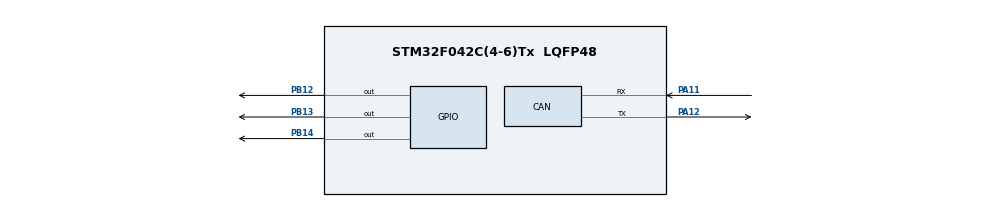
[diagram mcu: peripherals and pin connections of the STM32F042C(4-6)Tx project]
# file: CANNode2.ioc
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CAN.CalculateTimeQuantum=2000.0
Mcu.Family=STM32F0
Mcu.Name=STM32F042C(4-6)Tx
Mcu.Package=LQFP48
PA11.Mode=Master
PA11.Signal=CAN_RX
PA12.Mode=Master
PA12.Signal=CAN_TX
PB12.Signal=GPIO_Output
PB13.Signal=GPIO_Output
PB14.Signal=GPIO_Output
ProjectManager.HeapSize=0x200
ProjectManager.StackSize=0x400
ProjectManager.TargetToolchain=STM32CubeIDE
board=custom

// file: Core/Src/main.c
/* USER CODE BEGIN Header */
/**
  ******************************************************************************
  * @file           : main.c
  * @brief          : Main program body
  ******************************************************************************
  * @attention
  *
  * <h2><center>&copy; Copyright (c) 2021 STMicroelectronics.
  * All rights reserved.</center></h2>
  *
  * This software component is licensed by ST under BSD 3-Clause license,
  * the "License"; You may not use this file except in compliance with the
  * License. You may obtain a copy of the License at:
  *                        opensource.org/licenses/BSD-3-Clause
  *
  ******************************************************************************
  */
/* USER CODE END Header */
#include "main.h"

CAN_HandleTypeDef hcan;

void SystemClock_Config(void);
static void MX_GPIO_Init(void);
static void MX_CAN_Init(void);

/* USER CODE BEGIN 0 */
uint8_t DATA;
/* USER CODE END 0 */

int main(void)
{

  /* MCU Configuration--------------------------------------------------------*/

  /* Reset of all peripherals, Initializes the Flash interface and the Systick. */
  HAL_Init();

  /* Configure the system clock */
  SystemClock_Config();

  /* Initialize all configured peripherals */
  MX_GPIO_Init();
  MX_CAN_Init();

  /* Infinite loop */
  while (1)
  {

  }
}

void SystemClock_Config(void)
{
  RCC_OscInitTypeDef RCC_OscInitStruct = {0};
  RCC_ClkInitTypeDef RCC_ClkInitStruct = {0};

  /** Initializes the RCC Oscillators according to the specified parameters
  * in the RCC_OscInitTypeDef structure.
  */
  RCC_OscInitStruct.OscillatorType = RCC_OSCILLATORTYPE_HSI;
  RCC_OscInitStruct.HSIState = RCC_HSI_ON;
  RCC_OscInitStruct.HSICalibrationValue = RCC_HSICALIBRATION_DEFAULT;
  RCC_OscInitStruct.PLL.PLLState = RCC_PLL_NONE;
  if (HAL_RCC_OscConfig(&RCC_OscInitStruct) != HAL_OK)
  {
    Error_Handler();
  }
  /** Initializes the CPU, AHB and APB buses clocks
  */
  RCC_ClkInitStruct.ClockType = RCC_CLOCKTYPE_HCLK|RCC_CLOCKTYPE_SYSCLK
                              |RCC_CLOCKTYPE_PCLK1;
  RCC_ClkInitStruct.SYSCLKSource = RCC_SYSCLKSOURCE_HSI;
  RCC_ClkInitStruct.AHBCLKDivider = RCC_SYSCLK_DIV1;
  RCC_ClkInitStruct.APB1CLKDivider = RCC_HCLK_DIV1;

  if (HAL_RCC_ClockConfig(&RCC_ClkInitStruct, FLASH_LATENCY_0) != HAL_OK)
  {
    Error_Handler();
  }
}

static void MX_CAN_Init(void)
{

  hcan.Instance = CAN;
  hcan.Init.Prescaler = 16;
  hcan.Init.Mode = CAN_MODE_NORMAL;
  hcan.Init.SyncJumpWidth = CAN_SJW_1TQ;
  hcan.Init.TimeSeg1 = CAN_BS1_1TQ;
  hcan.Init.TimeSeg2 = CAN_BS2_1TQ;
  hcan.Init.TimeTriggeredMode = DISABLE;
  hcan.Init.AutoBusOff = DISABLE;
  hcan.Init.AutoWakeUp = DISABLE;
  hcan.Init.AutoRetransmission = DISABLE;
  hcan.Init.ReceiveFifoLocked = DISABLE;
  hcan.Init.TransmitFifoPriority = DISABLE;
  if (HAL_CAN_Init(&hcan) != HAL_OK)
  {
    Error_Handler();
  }

}

static void MX_GPIO_Init(void)
{
  GPIO_InitTypeDef GPIO_InitStruct = {0};

  /* GPIO Ports Clock Enable */
  __HAL_RCC_GPIOB_CLK_ENABLE();
  __HAL_RCC_GPIOA_CLK_ENABLE();

  /*Configure GPIO pin Output Level */
  HAL_GPIO_WritePin(GPIOB, GPIO_PIN_12|GPIO_PIN_13|GPIO_PIN_14, GPIO_PIN_RESET);

  /*Configure GPIO pins : PB12 PB13 PB14 */
  GPIO_InitStruct.Pin = GPIO_PIN_12|GPIO_PIN_13|GPIO_PIN_14;
  GPIO_InitStruct.Mode = GPIO_MODE_OUTPUT_PP;
  GPIO_InitStruct.Pull = GPIO_NOPULL;
  GPIO_InitStruct.Speed = GPIO_SPEED_FREQ_LOW;
  HAL_GPIO_Init(GPIOB, &GPIO_InitStruct);

}

void Error_Handler(void)
{
}

/************************ (C) COPYRIGHT STMicroelectronics *****END OF FILE****/
